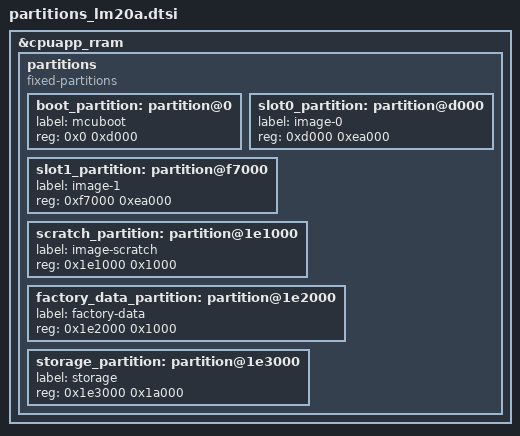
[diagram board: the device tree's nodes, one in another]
&cpuapp_rram {
        /delete-node/ partitions;

        partitions {
                compatible = "fixed-partitions";
                #address-cells = <1>;
                #size-cells = <1>;

                boot_partition: partition@0 {
                        label = "mcuboot";
                        reg = <0x0 0xd000>;
                };

                slot0_partition: partition@d000 {
                        label = "image-0";
                        reg = <0xd000 0xea000>;
                };

                slot1_partition: partition@f7000 {
                        label = "image-1";
                        reg = <0xf7000 0xea000>;
                };

                scratch_partition: partition@1e1000 {
                        label = "image-scratch";
                        reg = <0x1e1000 0x1000>;
                };

                factory_data_partition: partition@1e2000 {
                        label = "factory-data";
                        reg = <0x1e2000 0x1000>;
                };

                storage_partition: partition@1e3000 {
                        label = "storage";
                        reg = <0x1e3000 0x1a000>;
                };
        };
};
